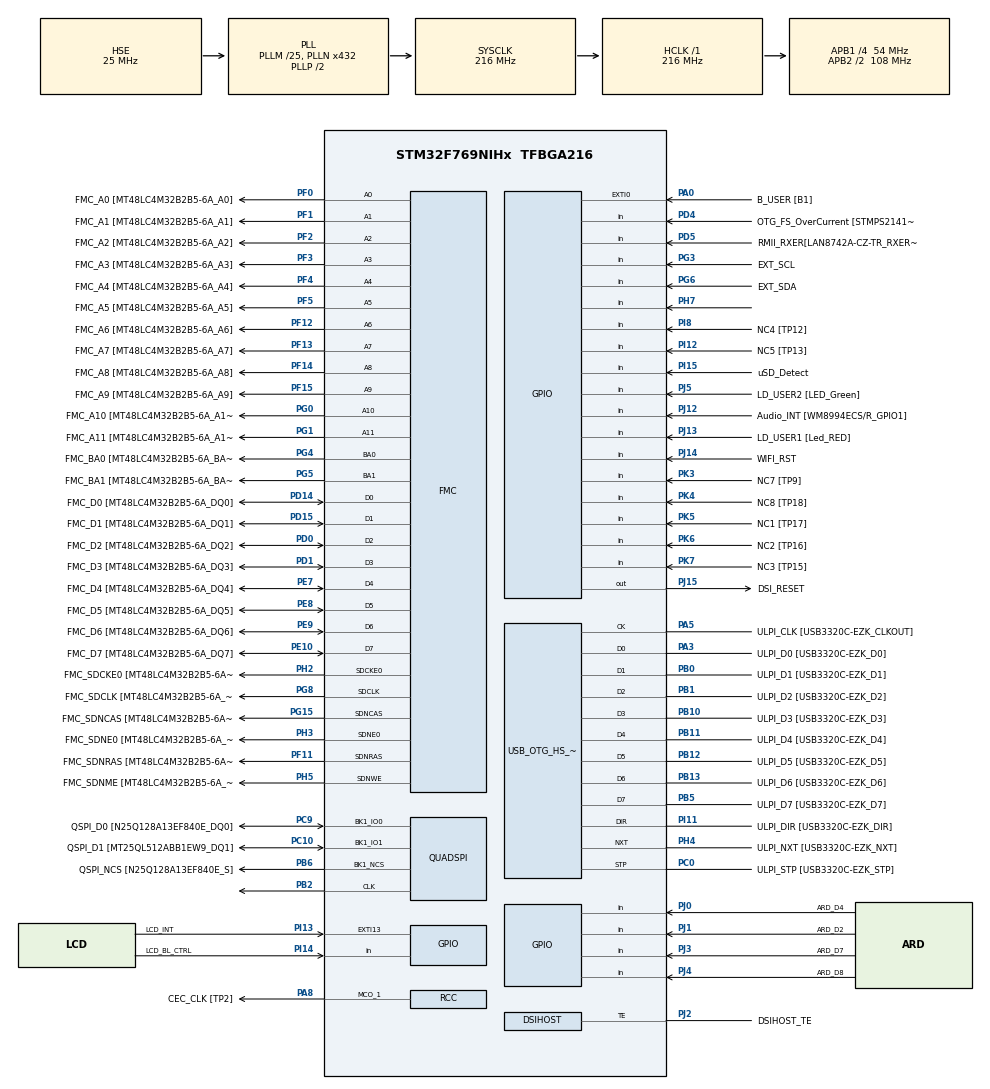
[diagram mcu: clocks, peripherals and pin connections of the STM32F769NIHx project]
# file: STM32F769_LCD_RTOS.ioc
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DSIHOST_CKN.GPIO_Label=DSI_CK_N
DSIHOST_CKN.Mode=DSIHost_Adapted_TE
DSIHOST_CKN.Signal=DSIHOST_CKN
DSIHOST_CKP.GPIO_Label=DSI_CK_P
DSIHOST_CKP.Mode=DSIHost_Adapted_TE
DSIHOST_CKP.Signal=DSIHOST_CKP
DSIHOST_D0N.GPIO_Label=DSI_D0_N
DSIHOST_D0N.Mode=DSIHost_Adapted_TE
DSIHOST_D0N.Signal=DSIHOST_D0N
DSIHOST_D0P.GPIO_Label=DSI_D0_p
DSIHOST_D0P.Mode=DSIHost_Adapted_TE
DSIHOST_D0P.Signal=DSIHOST_D0P
DSIHOST_D1N.GPIO_Label=DSI_D1_N
DSIHOST_D1N.Mode=DSIHost_Adapted_TE
DSIHOST_D1N.Signal=DSIHOST_D1N
DSIHOST_D1P.GPIO_Label=DSI_D1_P
DSIHOST_D1P.Mode=DSIHost_Adapted_TE
DSIHOST_D1P.Signal=DSIHOST_D1P
FREERTOS.Tasks01=defaultTask,24,4096,StartDefaultTask,Default,NULL,Dynamic,NULL,NULL
FREERTOS.configCHECK_FOR_STACK_OVERFLOW=2
FREERTOS.configTOTAL_HEAP_SIZE=32768
FREERTOS.configUSE_APPLICATION_TASK_TAG=1
FREERTOS.configUSE_COUNTING_SEMAPHORES=1
FREERTOS.configUSE_IDLE_HOOK=1
FREERTOS.configUSE_MALLOC_FAILED_HOOK=1
FREERTOS.configUSE_RECURSIVE_MUTEXES=1
LTDC.ActiveW=200
LTDC.Alpha_L0=255
LTDC.BlendingFactor1_L0=LTDC_BLENDING_FACTOR1_PAxCA
LTDC.BlendingFactor2_L0=LTDC_BLENDING_FACTOR2_PAxCA
LTDC.FBStartAdress_L0=0xC0000000
LTDC.HBP=1
LTDC.HFP=1
LTDC.HSync=1
LTDC.ImageHeight_L0=480
LTDC.ImageWidth_L0=200
LTDC.Layers=0
LTDC.PixelFormat_L0=LTDC_PIXEL_FORMAT_RGB565
LTDC.VBP=1
LTDC.VFP=1
LTDC.VSync=1
LTDC.WindowX1_L0=200
LTDC.WindowY1_L0=480
Mcu.Family=STM32F7
Mcu.Name=STM32F769NIHx
Mcu.Package=TFBGA216
NVIC.DMA2D_IRQn=true\:5\:0\:false\:false\:true\:true\:true\:true
NVIC.LTDC_IRQn=true\:5\:0\:false\:false\:true\:true\:true\:true
NVIC.OTG_HS_IRQn=true\:5\:0\:false\:false\:true\:true\:true\:true
NVIC.PriorityGroup=NVIC_PRIORITYGROUP_4
NVIC.TIM6_DAC_IRQn=true\:0\:0\:false\:false\:true\:false\:false\:true
NVIC.TimeBase=TIM6_DAC_IRQn
NVIC.TimeBaseIP=TIM6
PA0/WKUP.GPIO_Label=B_USER [B1]
PA0/WKUP.Signal=GPXTI0
PA1.GPIO_Label=RMII_REF_CLK [LAN8742A-CZ-TR_REFCLK0]
PA1.Signal=ETH_REF_CLK
PA10.GPIO_Label=VCP_RX 
PA10.Signal=USART1_RX
PA11.GPIO_Label=SPI2_NSS
PA11.Signal=SPI2_NSS
PA12.GPIO_Label=ARD_D13/SCK
PA12.GPIO_Mode=GPIO_MODE_AF_PP
PA12.GPIO_PuPd=GPIO_NOPULL
PA12.GPIO_Speed=GPIO_SPEED_FREQ_LOW
PA12.Signal=SPI2_SCK
PA13.GPIO_Label=SWDIO
PA13.Mode=Serial_Wire
PA13.Signal=SYS_JTMS-SWDIO
PA14.GPIO_Label=SWCLK
PA14.Mode=Serial_Wire
PA14.Signal=SYS_JTCK-SWCLK
PA15.GPIO_Label=CEC
PA15.Signal=CEC
PA2.GPIO_Label=RMII_MDIO [LAN8742A-CZ-TR_MDIO]
PA2.Signal=ETH_MDIO
PA3.GPIO_Label=ULPI_D0 [USB3320C-EZK_D0]
PA3.Mode=Device_HS
PA3.Signal=USB_OTG_HS_ULPI_D0
PA4.GPIO_Label=ARD_A1
PA4.Signal=ADCx_IN4
PA5.GPIO_Label=ULPI_CLK [USB3320C-EZK_CLKOUT]
PA5.Mode=Device_HS
PA5.Signal=USB_OTG_HS_ULPI_CK
PA6.GPIO_Label=ARD_A0
PA6.Signal=ADCx_IN6
PA7.GPIO_Label=RMII_CRS_DV [LAN8742A-CZ-TR_CRS_DV]
PA7.Signal=ETH_CRS_DV
PA8.GPIO_Label=CEC_CLK [TP2]
PA8.Mode=Clock-out-1
PA8.Signal=RCC_MCO_1
PA9.GPIO_Label=VCP_TX [STM32F103CBT6_PA3]
PA9.GPIO_Mode=GPIO_MODE_AF_PP
PA9.GPIO_PuPd=GPIO_NOPULL
PA9.GPIO_Speed=GPIO_SPEED_FREQ_LOW
PA9.Signal=USART1_TX
PB0.GPIO_Label=ULPI_D1 [USB3320C-EZK_D1]
PB0.Mode=Device_HS
PB0.Signal=USB_OTG_HS_ULPI_D1
PB1.GPIO_Label=ULPI_D2 [USB3320C-EZK_D2]
PB1.Mode=Device_HS
PB1.Signal=USB_OTG_HS_ULPI_D2
PB10.GPIO_Label=ULPI_D3 [USB3320C-EZK_D3]
PB10.Mode=Device_HS
PB10.Signal=USB_OTG_HS_ULPI_D3
PB11.GPIO_Label=ULPI_D4 [USB3320C-EZK_D4]
PB11.Mode=Device_HS
PB11.Signal=USB_OTG_HS_ULPI_D4
PB12.GPIO_Label=ULPI_D5 [USB3320C-EZK_D5]
PB12.Mode=Device_HS
PB12.Signal=USB_OTG_HS_ULPI_D5
PB13.GPIO_Label=ULPI_D6 [USB3320C-EZK_D6]
PB13.Mode=Device_HS
PB13.Signal=USB_OTG_HS_ULPI_D6
PB14.GPIO_Label=ARDUINO MISO/D12
PB14.GPIO_Mode=GPIO_MODE_AF_PP
PB14.GPIO_PuPd=GPIO_NOPULL
PB14.GPIO_Speed=GPIO_SPEED_FREQ_LOW
PB14.Signal=SPI2_MISO
PB15.GPIO_Label=ARDUINO MOSI/PWM/D11
PB15.GPIO_Mode=GPIO_MODE_AF_PP
PB15.GPIO_PuPd=GPIO_NOPULL
PB15.GPIO_Speed=GPIO_SPEED_FREQ_LOW
PB15.Signal=SPI2_MOSI
PB2.Mode=Single Bank 1 2IOs
PB2.Signal=QUADSPI_CLK
PB3.GPIO_Label=uSD_D2
PB3.Signal=SDMMC2_D2
PB4.GPIO_Label=uSD_D3
PB4.Signal=SDMMC2_D3
PB5.GPIO_Label=ULPI_D7 [USB3320C-EZK_D7]
PB5.Mode=Device_HS
PB5.Signal=USB_OTG_HS_ULPI_D7
PB6.GPIO_Label=QSPI_NCS [N25Q128A13EF840E_S]
PB6.Mode=Single Bank 1 2IOs
PB6.Signal=QUADSPI_BK1_NCS
PB7.GPIO_Label=AUDIO_SDA [WM8994ECS/R_SDA]
PB7.Signal=I2C4_SDA
PB8.GPIO_Label=ARDUINO SCL/D15
PB8.GPIO_Mode=GPIO_MODE_AF_OD
PB8.GPIO_PuPd=GPIO_NOPULL
PB8.GPIO_Speed=GPIO_SPEED_FREQ_LOW
PB8.Signal=I2C1_SCL
PB9.GPIO_Label=ARDUINO SDA/D14
PB9.GPIO_Mode=GPIO_MODE_AF_OD
PB9.GPIO_PuPd=GPIO_NOPULL
PB9.GPIO_Speed=GPIO_SPEED_FREQ_LOW
PB9.Signal=I2C1_SDA
PC0.GPIO_Label=ULPI_STP [USB3320C-EZK_STP]
PC0.Mode=Device_HS
PC0.Signal=USB_OTG_HS_ULPI_STP
PC1.GPIO_Label=RMII_MDC [LAN8742A-CZ-TR_MDC]
PC1.Signal=ETH_MDC
PC10.GPIO_Label=QSPI_D1 [MT25QL512ABB1EW9_DQ1]
PC10.Mode=Single Bank 1 2IOs
PC10.Signal=QUADSPI_BK1_IO1
PC11.GPIO_Label=DFSDM_DATIN5 [TP5]
PC11.Signal=S_DATAIN5DFSDM1
PC12.GPIO_Label=WIFI_RX
PC12.Signal=UART5_TX
PC13.Signal=RTC_OUT_ALARM
PC14/OSC32_IN.GPIO_Label=RCC_OSC32_IN
PC14/OSC32_IN.Mode=LSE-External-Oscillator
PC14/OSC32_IN.Signal=RCC_OSC32_IN
PC15/OSC32_OUT.GPIO_Label=RCC_OSC32_OUT
PC15/OSC32_OUT.Mode=LSE-External-Oscillator
PC15/OSC32_OUT.Signal=RCC_OSC32_OUT
PC2.GPIO_Label=ARD_A2
PC2.Signal=ADCx_IN12
PC4.GPIO_Label=RMII_RXD0 [LAN8742A-CZ-TR_RXD0]
PC4.Signal=ETH_RXD0
PC5.GPIO_Label=RMII_RXD1 [LAN8742A-CZ-TR_RXD1]
PC5.Signal=ETH_RXD1
PC6.GPIO_Label=ARDUINO TX/D1
PC6.Signal=USART6_TX
PC7.GPIO_Label=ARD_D0/RX
PC7.Signal=USART6_RX
PC8.GPIO_Label=ARD_D5/PWM
PC8.Signal=S_TIM3_CH3
PC9.GPIO_Label=QSPI_D0 [N25Q128A13EF840E_DQ0]
PC9.Mode=Single Bank 1 2IOs
PC9.Signal=QUADSPI_BK1_IO0
PD0.GPIO_Label=FMC_D2 [MT48LC4M32B2B5-6A_DQ2]
PD0.Signal=FMC_D2_DA2
PD1.GPIO_Label=FMC_D3 [MT48LC4M32B2B5-6A_DQ3]
PD1.Signal=FMC_D3_DA3
PD10.GPIO_Label=FMC_D15 [MT48LC4M32B2B5-6A_DQ15]
PD10.Signal=FMC_D15_DA15
PD11.GPIO_Label=SPDIF_TX [TP20]
PD11.Signal=SAI2_SD_A
PD12.GPIO_Label=AUDIO_SCL [WM8994ECS/R_SCLK]
PD12.Signal=I2C4_SCL
PD13.GPIO_Label=QSPI_D3 [N25Q128A13EF840E_DQ3]
PD13.Signal=QUADSPI_BK1_IO3
PD14.GPIO_Label=FMC_D0 [MT48LC4M32B2B5-6A_DQ0]
PD14.Signal=FMC_D0_DA0
PD15.GPIO_Label=FMC_D1 [MT48LC4M32B2B5-6A_DQ1]
PD15.Signal=FMC_D1_DA1
PD2.GPIO_Label=WIFI_TX
PD2.Signal=UART5_RX
PD3.GPIO_Label=DFSDM_CKOUT [TP102]
PD3.Signal=S_CKOUTDFSDM1
PD4.GPIO_Label=OTG_FS_OverCurrent [STMPS2141STR_Fault]
PD4.Signal=GPIO_Input
PD5.GPIO_Label=RMII_RXER[LAN8742A-CZ-TR_RXERR]
PD5.Signal=GPIO_Input
PD6.GPIO_Label=uSD_CLK
PD6.Signal=SDMMC2_CK
PD7.GPIO_Label=uSD_CMD
PD7.Signal=SDMMC2_CMD
PD8.GPIO_Label=FMC_D13 [MT48LC4M32B2B5-6A_DQ13]
PD8.Signal=FMC_D13_DA13
PD9.GPIO_Label=FMC_D14 [MT48LC4M32B2B5-6A_DQ14]
PD9.Signal=FMC_D14_DA14
PE0.GPIO_Label=FMC_NBL0 [MT48LC4M32B2B5-6A_DQM0]
PE0.Signal=FMC_NBL0
PE1.GPIO_Label=FMC_NBL1 [MT48LC4M32B2B5-6A_DQM1]
PE1.Signal=FMC_NBL1
PE10.GPIO_Label=FMC_D7 [MT48LC4M32B2B5-6A_DQ7]
PE10.Signal=FMC_D7_DA7
PE11.GPIO_Label=FMC_D8 [MT48LC4M32B2B5-6A_DQ8]
PE11.Signal=FMC_D8_DA8
PE12.GPIO_Label=FMC_D9 [MT48LC4M32B2B5-6A_DQ9]
PE12.Signal=FMC_D9_DA9
PE13.GPIO_Label=FMC_D10 [MT48LC4M32B2B5-6A_DQ10]
PE13.Signal=FMC_D10_DA10
PE14.GPIO_Label=FMC_D11 [MT48LC4M32B2B5-6A_DQ11]
PE14.Signal=FMC_D11_DA11
PE15.GPIO_Label=FMC_D12 [MT48LC4M32B2B5-6A_DQ12]
PE15.Signal=FMC_D12_DA12
PE2.GPIO_Label=QSPI_D2 [N25Q128A13EF840E_DQ2]
PE2.Signal=QUADSPI_BK1_IO2
PE3.GPIO_Label=SAI1_SDB [WM8994ECS/R_ADCDAT1]
PE3.Signal=SAI1_SD_B
PE4.GPIO_Label=SAI1_FSA [WM8994ECS/R_LRCLK1]
PE4.Signal=SAI1_FS_A
PE5.GPIO_Label=SAI1_SCKA [WM8994ECS/R_BCLK1]
PE5.Signal=SAI1_SCK_A
PE6.GPIO_Label=SAI1_SDA [WM8994ECS/R_DACDAT1]
PE6.Signal=SAI1_SD_A
PE7.GPIO_Label=FMC_D4 [MT48LC4M32B2B5-6A_DQ4]
PE7.Signal=FMC_D4_DA4
PE8.GPIO_Label=FMC_D5 [MT48LC4M32B2B5-6A_DQ5]
PE8.Signal=FMC_D5_DA5
PE9.GPIO_Label=FMC_D6 [MT48LC4M32B2B5-6A_DQ6]
PE9.Signal=FMC_D6_DA6
PF0.GPIO_Label=FMC_A0 [MT48LC4M32B2B5-6A_A0]
PF0.Signal=FMC_A0
PF1.GPIO_Label=FMC_A1 [MT48LC4M32B2B5-6A_A1]
PF1.Signal=FMC_A1
PF10.GPIO_Label=ARDUINO A1
PF10.GPIO_Mode=GPIO_MODE_ANALOG
PF10.GPIO_PuPd=GPIO_NOPULL
PF10.Signal=ADC3_IN8
PF11.GPIO_Label=FMC_SDNRAS [MT48LC4M32B2B5-6A_RAS]
PF11.Signal=FMC_SDNRAS
PF12.GPIO_Label=FMC_A6 [MT48LC4M32B2B5-6A_A6]
PF12.Signal=FMC_A6
PF13.GPIO_Label=FMC_A7 [MT48LC4M32B2B5-6A_A7]
PF13.Signal=FMC_A7
PF14.GPIO_Label=FMC_A8 [MT48LC4M32B2B5-6A_A8]
PF14.Signal=FMC_A8
PF15.GPIO_Label=FMC_A9 [MT48LC4M32B2B5-6A_A9]
PF15.Signal=FMC_A9
PF2.GPIO_Label=FMC_A2 [MT48LC4M32B2B5-6A_A2]
PF2.Signal=FMC_A2
PF3.GPIO_Label=FMC_A3 [MT48LC4M32B2B5-6A_A3]
PF3.Signal=FMC_A3
PF4.GPIO_Label=FMC_A4 [MT48LC4M32B2B5-6A_A4]
PF4.Signal=FMC_A4
PF5.GPIO_Label=FMC_A5 [MT48LC4M32B2B5-6A_A5]
PF5.Signal=FMC_A5
PF6.GPIO_Label=ARD_D3/PWM
PF6.Signal=S_TIM10_CH1
PF7.GPIO_Label=ARD_D6/PWM
PF7.Signal=S_TIM11_CH1
PF8.GPIO_Label=ARDUINO A3
PF8.GPIO_Mode=GPIO_MODE_ANALOG
PF8.GPIO_PuPd=GPIO_NOPULL
PF8.Signal=ADC3_IN6
PF9.GPIO_Label=ARDUINO A2
PF9.GPIO_Mode=GPIO_MODE_ANALOG
PF9.GPIO_PuPd=GPIO_NOPULL
PF9.Signal=ADC3_IN7
PG0.GPIO_Label=FMC_A10 [MT48LC4M32B2B5-6A_A10]
PG0.Signal=FMC_A10
PG1.GPIO_Label=FMC_A11 [MT48LC4M32B2B5-6A_A11]
PG1.Signal=FMC_A11
PG10.GPIO_Label=uSD_D1
PG10.Signal=SDMMC2_D1
PG11.GPIO_Label=RMII_TX_EN [LAN8742A-CZ-TR_TXEN]
PG11.Signal=ETH_TX_EN
PG12.GPIO_Label=SPDIF_RX [74LVC1G04SE_4]
PG12.Signal=SPDIFRX_IN1
PG13.GPIO_Label=RMII_TXD0 [LAN8742A-CZ-TR_TXD0]
PG13.Signal=ETH_TXD0
PG14.GPIO_Label=RMII_TXD1 [LAN8742A-CZ-TR_TXD1]
PG14.Signal=ETH_TXD1
PG15.GPIO_Label=FMC_SDNCAS [MT48LC4M32B2B5-6A_CAS]
PG15.Signal=FMC_SDNCAS
PG2.GPIO_Label=FMC_A12
PG2.Signal=FMC_A12
PG3.GPIO_Label=EXT_SCL
PG3.Signal=GPIO_Input
PG4.GPIO_Label=FMC_BA0 [MT48LC4M32B2B5-6A_BA0]
PG4.Signal=FMC_A14_BA0
PG5.GPIO_Label=FMC_BA1 [MT48LC4M32B2B5-6A_BA1]
PG5.Signal=FMC_A15_BA1
PG6.GPIO_Label=EXT_SDA
PG6.Signal=GPIO_Input
PG7.GPIO_Label=SAI1_MCLKA [WM8994ECS/R_MCLK1]
PG7.Signal=SAI1_MCLK_A
PG8.GPIO_Label=FMC_SDCLK [MT48LC4M32B2B5-6A_CLK]
PG8.Signal=FMC_SDCLK
PG9.GPIO_Label=uSD_D0
PG9.Signal=SDMMC2_D0
PH0/OSC_IN.GPIO_Label=OSC_25M [NZ2520SB-25.00M_OUT]
PH0/OSC_IN.Mode=HSE-External-Oscillator
PH0/OSC_IN.Signal=RCC_OSC_IN
PH1/OSC_OUT.Mode=HSE-External-Oscillator
PH1/OSC_OUT.Signal=RCC_OSC_OUT
PH10.GPIO_Label=FMC_D18 [MT48LC4M32B2B5-6A_DQ18]
PH10.Signal=FMC_D18
PH11.GPIO_Label=FMC_D19 [MT48LC4M32B2B5-6A_DQ19]
PH11.Signal=FMC_D19
PH12.GPIO_Label=D20
PH12.Signal=FMC_D20
PH13.GPIO_Label=D21
PH13.Signal=FMC_D21
PH14.GPIO_Label=D22
PH14.Signal=FMC_D22
PH15.GPIO_Label=D23
PH15.Signal=FMC_D23
PH2.GPIO_Label=FMC_SDCKE0 [MT48LC4M32B2B5-6A_CKE]
PH2.Mode=SdramChipSelect1_2
PH2.Signal=FMC_SDCKE0
PH3.GPIO_Label=FMC_SDNE0 [MT48LC4M32B2B5-6A_CS]
PH3.Mode=SdramChipSelect1_2
PH3.Signal=FMC_SDNE0
PH4.GPIO_Label=ULPI_NXT [USB3320C-EZK_NXT]
PH4.Mode=Device_HS
PH4.Signal=USB_OTG_HS_ULPI_NXT
PH5.GPIO_Label=FMC_SDNME [MT48LC4M32B2B5-6A_WE]
PH5.Signal=FMC_SDNWE
PH6.GPIO_Label=ARDUINO PWM/D6
PH6.Signal=S_TIM12_CH1
PH7.Signal=GPIO_Input
PH8.GPIO_Label=FMC_D16 [MT48LC4M32B2B5-6A_DQ16]
PH8.Signal=FMC_D16
PH9.GPIO_Label=FMC_D\!7 [MT48LC4M32B2B5-6A_DQ17]
PH9.Signal=FMC_D17
PI0.GPIO_Label=D24
PI0.Signal=FMC_D24
PI1.GPIO_Label=D25
PI1.Signal=FMC_D25
PI10.GPIO_Label=D31
PI10.Signal=FMC_D31
PI11.GPIO_Label=ULPI_DIR [USB3320C-EZK_DIR]
PI11.Mode=Device_HS
PI11.Signal=USB_OTG_HS_ULPI_DIR
PI12.GPIO_Label=NC5 [TP13]
PI12.Signal=GPIO_Input
PI13.GPIO_Label=LCD_INT
PI13.GPIO_ModeDefaultEXTI=GPIO_MODE_EVT_RISING
PI13.Signal=GPXTI13
PI14.GPIO_Label=LCD_BL_CTRL
PI14.Signal=GPIO_Input
PI15.GPIO_Label=uSD_Detect
PI15.Signal=GPIO_Input
PI2.GPIO_Label=D26
PI2.Signal=FMC_D26
PI3.GPIO_Label=D27
PI3.Signal=FMC_D27
PI4.GPIO_Label=FMC_NBL2 [MT48LC4M32B2B5-6A_DQM2]
PI4.Signal=FMC_NBL2
PI5.GPIO_Label=FMC_NBL3 [MT48LC4M32B2B5-6A_DQM3]
PI5.Signal=FMC_NBL3
PI6.GPIO_Label=D28
PI6.Signal=FMC_D28
PI7.GPIO_Label=D29
PI7.Signal=FMC_D29
PI8.GPIO_Label=NC4 [TP12]
PI8.Signal=GPIO_Input
PI9.GPIO_Label=D30
PI9.Signal=FMC_D30
PJ0.GPIO_Label=ARD_D4
PJ0.Signal=GPIO_Input
PJ1.GPIO_Label=ARD_D2
PJ1.Signal=GPIO_Input
PJ12.GPIO_Label=Audio_INT [WM8994ECS/R_GPIO1]
PJ12.Signal=GPIO_Input
PJ13.GPIO_Label=LD_USER1 [Led_RED]
PJ13.Signal=GPIO_Input
PJ14.GPIO_Label=WIFI_RST
PJ14.Signal=GPIO_Input
PJ15.GPIO_Label=DSI_RESET
PJ15.Signal=GPIO_Output
PJ2.GPIO_Label=DSIHOST_TE
PJ2.Mode=DSIHost_Adapted_TE
PJ2.Signal=DSIHOST_TE
PJ3.GPIO_Label=ARD_D7
PJ3.Signal=GPIO_Input
PJ4.GPIO_Label=ARD_D8
PJ4.Signal=GPIO_Input
PJ5.GPIO_Label=LD_USER2 [LED_Green]
PJ5.Signal=GPIO_Input
PK3.GPIO_Label=NC7 [TP9]
PK3.Signal=GPIO_Input
PK4.GPIO_Label=NC8 [TP18]
PK4.Signal=GPIO_Input
PK5.GPIO_Label=NC1 [TP17]
PK5.Signal=GPIO_Input
PK6.GPIO_Label=NC2 [TP16]
PK6.Signal=GPIO_Input
PK7.GPIO_Label=NC3 [TP15]
PK7.Signal=GPIO_Input
ProjectManager.HeapSize=0x200
ProjectManager.StackSize=0x400
ProjectManager.TargetToolchain=STM32CubeIDE
RCC.AHBFreq_Value=216000000
RCC.APB1CLKDivider=RCC_HCLK_DIV4
RCC.APB1Freq_Value=54000000
RCC.APB1TimFreq_Value=108000000
RCC.APB2CLKDivider=RCC_HCLK_DIV2
RCC.APB2Freq_Value=108000000
RCC.APB2TimFreq_Value=216000000
RCC.CortexFreq_Value=216000000
RCC.HCLKFreq_Value=216000000
RCC.HSE_VALUE=25000000
RCC.HSI_VALUE=16000000
RCC.PLL48CLockSelection=RCC_CLK48SOURCE_PLLSAIP
RCC.PLLM=25
RCC.PLLN=432
RCC.PLLQ=4
RCC.PLLSAIP=RCC_PLLSAIP_DIV4
RCC.PLLSAIQ=3
RCC.PLLSourceVirtual=RCC_PLLSOURCE_HSE
RCC.SDMMC2ClockSelection=RCC_SDMMC2CLKSOURCE_CLK48
RCC.SYSCLKFreq_VALUE=216000000
RCC.SYSCLKSource=RCC_SYSCLKSOURCE_PLLCLK
RCC.USBFreq_Value=48000000
RCC.VCOOutputFreq_Value=432000000
SH.ADCx_IN12.0=ADC1_IN12
SH.ADCx_IN4.0=ADC1_IN4
SH.ADCx_IN6.0=ADC1_IN6
SH.FMC_A0.0=FMC_A0,12b-sda2
SH.FMC_A1.0=FMC_A1,12b-sda2
SH.FMC_A10.0=FMC_A10,12b-sda2
SH.FMC_A11.0=FMC_A11,12b-sda2
SH.FMC_A12.0=FMC_A12
SH.FMC_A14_BA0.0=FMC_BA0,FourSdramBanks2
SH.FMC_A15_BA1.0=FMC_BA1,FourSdramBanks2
SH.FMC_A2.0=FMC_A2,12b-sda2
SH.FMC_A3.0=FMC_A3,12b-sda2
SH.FMC_A4.0=FMC_A4,12b-sda2
SH.FMC_A5.0=FMC_A5,12b-sda2
SH.FMC_A6.0=FMC_A6,12b-sda2
SH.FMC_A7.0=FMC_A7,12b-sda2
SH.FMC_A8.0=FMC_A8,12b-sda2
SH.FMC_A9.0=FMC_A9,12b-sda2
SH.FMC_D0_DA0.0=FMC_D0,sd-8b-d2
SH.FMC_D10_DA10.0=FMC_D10
SH.FMC_D11_DA11.0=FMC_D11
SH.FMC_D12_DA12.0=FMC_D12
SH.FMC_D13_DA13.0=FMC_D13
SH.FMC_D14_DA14.0=FMC_D14
SH.FMC_D15_DA15.0=FMC_D15
SH.FMC_D16.0=FMC_D16
SH.FMC_D17.0=FMC_D17
SH.FMC_D18.0=FMC_D18
SH.FMC_D19.0=FMC_D19
SH.FMC_D1_DA1.0=FMC_D1,sd-8b-d2
SH.FMC_D20.0=FMC_D20
SH.FMC_D21.0=FMC_D21
SH.FMC_D22.0=FMC_D22
SH.FMC_D23.0=FMC_D23
SH.FMC_D24.0=FMC_D24
SH.FMC_D25.0=FMC_D25
SH.FMC_D26.0=FMC_D26
SH.FMC_D27.0=FMC_D27
SH.FMC_D28.0=FMC_D28
SH.FMC_D29.0=FMC_D29
SH.FMC_D2_DA2.0=FMC_D2,sd-8b-d2
SH.FMC_D30.0=FMC_D30
SH.FMC_D31.0=FMC_D31
SH.FMC_D3_DA3.0=FMC_D3,sd-8b-d2
SH.FMC_D4_DA4.0=FMC_D4,sd-8b-d2
SH.FMC_D5_DA5.0=FMC_D5,sd-8b-d2
SH.FMC_D6_DA6.0=FMC_D6,sd-8b-d2
SH.FMC_D7_DA7.0=FMC_D7,sd-8b-d2
SH.FMC_D8_DA8.0=FMC_D8
SH.FMC_D9_DA9.0=FMC_D9
SH.FMC_NBL0.0=FMC_NBL0
SH.FMC_NBL1.0=FMC_NBL1
SH.FMC_NBL2.0=FMC_NBL2
SH.FMC_NBL3.0=FMC_NBL3
SH.FMC_SDCLK.0=FMC_SDCLK,12b-sda2
SH.FMC_SDNCAS.0=FMC_SDNCAS,12b-sda2
SH.FMC_SDNRAS.0=FMC_SDNRAS,12b-sda2
SH.FMC_SDNWE.0=FMC_SDNWE,12b-sda2
SH.S_CKOUTDFSDM1.0=DFSDM1_CKOUT
SH.S_DATAIN5DFSDM1.0=DFSDM1_DATIN5
SH.S_TIM10_CH1.0=TIM10_CH1
SH.S_TIM11_CH1.0=TIM11_CH1
SH.S_TIM12_CH1.0=TIM12_CH1
SH.S_TIM3_CH3.0=TIM3_CH3
USB_OTG_HS.VirtualMode-Device_HS=Device_HS
VP_DMA2D_VS_DMA2D.Mode=DMA2D_Activate
VP_FREERTOS_VS_CMSIS_V2.Mode=CMSIS_V2
VP_LTDC_DSIMode.Mode=RGB888
VP_SYS_VS_tim6.Mode=TIM6
VP_WWDG_VS_WWDG.Mode=WWDG_Activate
WWDG.Counter=128
board=STM32F769I-DISCO

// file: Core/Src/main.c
/* USER CODE BEGIN Header */
/**
  ******************************************************************************
  * @file           : main.c
  * @brief          : Main program body
  ******************************************************************************
  * @attention
  *
  * <h2><center>&copy; Copyright (c) 2019 STMicroelectronics.
  * All rights reserved.</center></h2>
  *
  * This software component is licensed by ST under Ultimate Liberty license
  * SLA0044, the "License"; You may not use this file except in compliance with
  * the License. You may obtain a copy of the License at:
  *                             www.st.com/SLA0044
  *
  ******************************************************************************
  */
/* USER CODE END Header */

#include "main.h"
#include "cmsis_os.h"

/* USER CODE BEGIN Includes */
#include "../../Drivers/BSP/STM32F769I-Discovery/stm32f769i_discovery.h"
#include "../../Drivers/BSP/STM32F769I-Discovery/stm32f769i_discovery_ts.h"
#include "../../Drivers/BSP/STM32F769I-Discovery/stm32f769i_discovery_lcd.h"
/* USER CODE END Includes */

DMA2D_HandleTypeDef hdma2d;

DSI_HandleTypeDef hdsi;

LTDC_HandleTypeDef hltdc;

QSPI_HandleTypeDef hqspi;

PCD_HandleTypeDef hpcd_USB_OTG_HS;

WWDG_HandleTypeDef hwwdg;

SDRAM_HandleTypeDef hsdram2;

osThreadId_t defaultTaskHandle;
/* USER CODE BEGIN PV */
osThreadId_t LCDTaskHandle;
/* USER CODE END PV */

void SystemClock_Config(void);
static void MX_GPIO_Init(void);
static void MX_DMA2D_Init(void);
static void MX_DSIHOST_DSI_Init(void);
static void MX_FMC_Init(void);
static void MX_LTDC_Init(void);
static void MX_QUADSPI_Init(void);
static void MX_USB_OTG_HS_PCD_Init(void);
static void MX_WWDG_Init(void);
void StartDefaultTask(void *argument);

/* USER CODE BEGIN PFP */
void LCDTask(void *argument);
/* USER CODE END PFP */

int main(void)
{

  /* MCU Configuration--------------------------------------------------------*/

  /* Reset of all peripherals, Initializes the Flash interface and the Systick. */
  HAL_Init();

  /* Configure the system clock */
  SystemClock_Config();

  /* Initialize all configured peripherals */

  /* USER CODE BEGIN 2 */
  BSP_LCD_Init();

  /* USER CODE END 2 */

  osKernelInitialize();

  /* Create the thread(s) */
  /* definition and creation of defaultTask */
  const osThreadAttr_t defaultTask_attributes = {
    .name = "defaultTask",
    .priority = (osPriority_t) osPriorityNormal,
    .stack_size = 4096
  };
  defaultTaskHandle = osThreadNew(StartDefaultTask, NULL, &defaultTask_attributes);

  /* USER CODE BEGIN RTOS_THREADS */
  /* add threads, ... */
  const osThreadAttr_t LCDtask_attributes = {
    .name = "LCDTask",
    .priority = (osPriority_t) osPriorityNormal,
    .stack_size = 4096
  };

  LCDTaskHandle = osThreadNew(LCDTask, NULL, &LCDtask_attributes);
  /* USER CODE END RTOS_THREADS */

  /* Start scheduler */
  osKernelStart();

  /* We should never get here as control is now taken by the scheduler */

  /* Infinite loop */
  while (1)
  {

  }
}

void SystemClock_Config(void)
{
  RCC_OscInitTypeDef RCC_OscInitStruct = {0};
  RCC_ClkInitTypeDef RCC_ClkInitStruct = {0};
  RCC_PeriphCLKInitTypeDef PeriphClkInitStruct = {0};

  /** Configure LSE Drive Capability
  */
  HAL_PWR_EnableBkUpAccess();
  /** Configure the main internal regulator output voltage
  */
  __HAL_RCC_PWR_CLK_ENABLE();
  __HAL_PWR_VOLTAGESCALING_CONFIG(PWR_REGULATOR_VOLTAGE_SCALE1);
  /** Initializes the CPU, AHB and APB busses clocks
  */
  RCC_OscInitStruct.OscillatorType = RCC_OSCILLATORTYPE_HSI|RCC_OSCILLATORTYPE_HSE;
  RCC_OscInitStruct.HSEState = RCC_HSE_ON;
  RCC_OscInitStruct.HSIState = RCC_HSI_ON;
  RCC_OscInitStruct.HSICalibrationValue = RCC_HSICALIBRATION_DEFAULT;
  RCC_OscInitStruct.PLL.PLLState = RCC_PLL_ON;
  RCC_OscInitStruct.PLL.PLLSource = RCC_PLLSOURCE_HSE;
  RCC_OscInitStruct.PLL.PLLM = 25;
  RCC_OscInitStruct.PLL.PLLN = 432;
  RCC_OscInitStruct.PLL.PLLP = RCC_PLLP_DIV2;
  RCC_OscInitStruct.PLL.PLLQ = 4;
  if (HAL_RCC_OscConfig(&RCC_OscInitStruct) != HAL_OK)
  {
    Error_Handler();
  }
  /** Activate the Over-Drive mode
  */
  if (HAL_PWREx_EnableOverDrive() != HAL_OK)
  {
    Error_Handler();
  }
  /** Initializes the CPU, AHB and APB busses clocks
  */
  RCC_ClkInitStruct.ClockType = RCC_CLOCKTYPE_HCLK|RCC_CLOCKTYPE_SYSCLK
                              |RCC_CLOCKTYPE_PCLK1|RCC_CLOCKTYPE_PCLK2;
  RCC_ClkInitStruct.SYSCLKSource = RCC_SYSCLKSOURCE_PLLCLK;
  RCC_ClkInitStruct.AHBCLKDivider = RCC_SYSCLK_DIV1;
  RCC_ClkInitStruct.APB1CLKDivider = RCC_HCLK_DIV4;
  RCC_ClkInitStruct.APB2CLKDivider = RCC_HCLK_DIV2;

  if (HAL_RCC_ClockConfig(&RCC_ClkInitStruct, FLASH_LATENCY_7) != HAL_OK)
  {
    Error_Handler();
  }
  PeriphClkInitStruct.PeriphClockSelection = RCC_PERIPHCLK_LTDC;
  PeriphClkInitStruct.PLLSAI.PLLSAIN = 192;
  PeriphClkInitStruct.PLLSAI.PLLSAIR = 2;
  PeriphClkInitStruct.PLLSAI.PLLSAIQ = 3;
  PeriphClkInitStruct.PLLSAI.PLLSAIP = RCC_PLLSAIP_DIV4;
  PeriphClkInitStruct.PLLSAIDivQ = 1;
  PeriphClkInitStruct.PLLSAIDivR = RCC_PLLSAIDIVR_2;
  if (HAL_RCCEx_PeriphCLKConfig(&PeriphClkInitStruct) != HAL_OK)
  {
    Error_Handler();
  }
  HAL_RCC_MCOConfig(RCC_MCO1, RCC_MCO1SOURCE_HSI, RCC_MCODIV_1);
}

static void MX_DMA2D_Init(void)
{

  hdma2d.Instance = DMA2D;
  hdma2d.Init.Mode = DMA2D_M2M;
  hdma2d.Init.ColorMode = DMA2D_OUTPUT_ARGB8888;
  hdma2d.Init.OutputOffset = 0;
  hdma2d.LayerCfg[1].InputOffset = 0;
  hdma2d.LayerCfg[1].InputColorMode = DMA2D_INPUT_ARGB8888;
  hdma2d.LayerCfg[1].AlphaMode = DMA2D_NO_MODIF_ALPHA;
  hdma2d.LayerCfg[1].InputAlpha = 0;
  hdma2d.LayerCfg[1].AlphaInverted = DMA2D_REGULAR_ALPHA;
  hdma2d.LayerCfg[1].RedBlueSwap = DMA2D_RB_REGULAR;
  if (HAL_DMA2D_Init(&hdma2d) != HAL_OK)
  {
    Error_Handler();
  }
  if (HAL_DMA2D_ConfigLayer(&hdma2d, 1) != HAL_OK)
  {
    Error_Handler();
  }

}

static void MX_DSIHOST_DSI_Init(void)
{

  DSI_PLLInitTypeDef PLLInit = {0};
  DSI_HOST_TimeoutTypeDef HostTimeouts = {0};
  DSI_PHY_TimerTypeDef PhyTimings = {0};
  DSI_LPCmdTypeDef LPCmd = {0};
  DSI_CmdCfgTypeDef CmdCfg = {0};

  hdsi.Instance = DSI;
  hdsi.Init.AutomaticClockLaneControl = DSI_AUTO_CLK_LANE_CTRL_DISABLE;
  hdsi.Init.TXEscapeCkdiv = 4;
  hdsi.Init.NumberOfLanes = DSI_ONE_DATA_LANE;
  PLLInit.PLLNDIV = 20;
  PLLInit.PLLIDF = DSI_PLL_IN_DIV1;
  PLLInit.PLLODF = DSI_PLL_OUT_DIV1;
  if (HAL_DSI_Init(&hdsi, &PLLInit) != HAL_OK)
  {
    Error_Handler();
  }
  HostTimeouts.TimeoutCkdiv = 1;
  HostTimeouts.HighSpeedTransmissionTimeout = 0;
  HostTimeouts.LowPowerReceptionTimeout = 0;
  HostTimeouts.HighSpeedReadTimeout = 0;
  HostTimeouts.LowPowerReadTimeout = 0;
  HostTimeouts.HighSpeedWriteTimeout = 0;
  HostTimeouts.HighSpeedWritePrespMode = DSI_HS_PM_DISABLE;
  HostTimeouts.LowPowerWriteTimeout = 0;
  HostTimeouts.BTATimeout = 0;
  if (HAL_DSI_ConfigHostTimeouts(&hdsi, &HostTimeouts) != HAL_OK)
  {
    Error_Handler();
  }
  PhyTimings.ClockLaneHS2LPTime = 28;
  PhyTimings.ClockLaneLP2HSTime = 33;
  PhyTimings.DataLaneHS2LPTime = 15;
  PhyTimings.DataLaneLP2HSTime = 25;
  PhyTimings.DataLaneMaxReadTime = 0;
  PhyTimings.StopWaitTime = 0;
  if (HAL_DSI_ConfigPhyTimer(&hdsi, &PhyTimings) != HAL_OK)
  {
    Error_Handler();
  }
  if (HAL_DSI_ConfigFlowControl(&hdsi, DSI_FLOW_CONTROL_BTA) != HAL_OK)
  {
    Error_Handler();
  }
  if (HAL_DSI_SetLowPowerRXFilter(&hdsi, 10000) != HAL_OK)
  {
    Error_Handler();
  }
  if (HAL_DSI_ConfigErrorMonitor(&hdsi, HAL_DSI_ERROR_NONE) != HAL_OK)
  {
    Error_Handler();
  }
  LPCmd.LPGenShortWriteNoP = DSI_LP_GSW0P_DISABLE;
  LPCmd.LPGenShortWriteOneP = DSI_LP_GSW1P_DISABLE;
  LPCmd.LPGenShortWriteTwoP = DSI_LP_GSW2P_DISABLE;
  LPCmd.LPGenShortReadNoP = DSI_LP_GSR0P_DISABLE;
  LPCmd.LPGenShortReadOneP = DSI_LP_GSR1P_DISABLE;
  LPCmd.LPGenShortReadTwoP = DSI_LP_GSR2P_DISABLE;
  LPCmd.LPGenLongWrite = DSI_LP_GLW_DISABLE;
  LPCmd.LPDcsShortWriteNoP = DSI_LP_DSW0P_DISABLE;
  LPCmd.LPDcsShortWriteOneP = DSI_LP_DSW1P_DISABLE;
  LPCmd.LPDcsShortReadNoP = DSI_LP_DSR0P_DISABLE;
  LPCmd.LPDcsLongWrite = DSI_LP_DLW_DISABLE;
  LPCmd.LPMaxReadPacket = DSI_LP_MRDP_DISABLE;
  LPCmd.AcknowledgeRequest = DSI_ACKNOWLEDGE_DISABLE;
  if (HAL_DSI_ConfigCommand(&hdsi, &LPCmd) != HAL_OK)
  {
    Error_Handler();
  }
  CmdCfg.VirtualChannelID = 0;
  CmdCfg.ColorCoding = DSI_RGB888;
  CmdCfg.CommandSize = 200;
  CmdCfg.TearingEffectSource = DSI_TE_EXTERNAL;
  CmdCfg.TearingEffectPolarity = DSI_TE_RISING_EDGE;
  CmdCfg.HSPolarity = DSI_HSYNC_ACTIVE_LOW;
  CmdCfg.VSPolarity = DSI_VSYNC_ACTIVE_LOW;
  CmdCfg.DEPolarity = DSI_DATA_ENABLE_ACTIVE_HIGH;
  CmdCfg.VSyncPol = DSI_VSYNC_FALLING;
  CmdCfg.AutomaticRefresh = DSI_AR_ENABLE;
  CmdCfg.TEAcknowledgeRequest = DSI_TE_ACKNOWLEDGE_DISABLE;
  if (HAL_DSI_ConfigAdaptedCommandMode(&hdsi, &CmdCfg) != HAL_OK)
  {
    Error_Handler();
  }
  if (HAL_DSI_SetGenericVCID(&hdsi, 0) != HAL_OK)
  {
    Error_Handler();
  }

}

static void MX_LTDC_Init(void)
{

  LTDC_LayerCfgTypeDef pLayerCfg = {0};

  hltdc.Instance = LTDC;
  hltdc.Init.HSPolarity = LTDC_HSPOLARITY_AL;
  hltdc.Init.VSPolarity = LTDC_VSPOLARITY_AL;
  hltdc.Init.DEPolarity = LTDC_DEPOLARITY_AL;
  hltdc.Init.PCPolarity = LTDC_PCPOLARITY_IPC;
  hltdc.Init.HorizontalSync = 0;
  hltdc.Init.VerticalSync = 0;
  hltdc.Init.AccumulatedHBP = 1;
  hltdc.Init.AccumulatedVBP = 1;
  hltdc.Init.AccumulatedActiveW = 201;
  hltdc.Init.AccumulatedActiveH = 481;
  hltdc.Init.TotalWidth = 202;
  hltdc.Init.TotalHeigh = 482;
  hltdc.Init.Backcolor.Blue = 0;
  hltdc.Init.Backcolor.Green = 0;
  hltdc.Init.Backcolor.Red = 0;
  if (HAL_LTDC_Init(&hltdc) != HAL_OK)
  {
    Error_Handler();
  }
  pLayerCfg.WindowX0 = 0;
  pLayerCfg.WindowX1 = 200;
  pLayerCfg.WindowY0 = 0;
  pLayerCfg.WindowY1 = 480;
  pLayerCfg.PixelFormat = LTDC_PIXEL_FORMAT_RGB565;
  pLayerCfg.Alpha = 255;
  pLayerCfg.Alpha0 = 0;
  pLayerCfg.BlendingFactor1 = LTDC_BLENDING_FACTOR1_PAxCA;
  pLayerCfg.BlendingFactor2 = LTDC_BLENDING_FACTOR2_PAxCA;
  pLayerCfg.FBStartAdress = 0xC0000000;
  pLayerCfg.ImageWidth = 200;
  pLayerCfg.ImageHeight = 480;
  pLayerCfg.Backcolor.Blue = 0;
  pLayerCfg.Backcolor.Green = 0;
  pLayerCfg.Backcolor.Red = 0;
  if (HAL_LTDC_ConfigLayer(&hltdc, &pLayerCfg, 0) != HAL_OK)
  {
    Error_Handler();
  }

}

static void MX_QUADSPI_Init(void)
{

  /* QUADSPI parameter configuration*/
  hqspi.Instance = QUADSPI;
  hqspi.Init.ClockPrescaler = 255;
  hqspi.Init.FifoThreshold = 1;
  hqspi.Init.SampleShifting = QSPI_SAMPLE_SHIFTING_NONE;
  hqspi.Init.FlashSize = 1;
  hqspi.Init.ChipSelectHighTime = QSPI_CS_HIGH_TIME_1_CYCLE;
  hqspi.Init.ClockMode = QSPI_CLOCK_MODE_0;
  hqspi.Init.FlashID = QSPI_FLASH_ID_1;
  hqspi.Init.DualFlash = QSPI_DUALFLASH_DISABLE;
  if (HAL_QSPI_Init(&hqspi) != HAL_OK)
  {
    Error_Handler();
  }

}

static void MX_USB_OTG_HS_PCD_Init(void)
{

  hpcd_USB_OTG_HS.Instance = USB_OTG_HS;
  hpcd_USB_OTG_HS.Init.dev_endpoints = 9;
  hpcd_USB_OTG_HS.Init.speed = PCD_SPEED_HIGH;
  hpcd_USB_OTG_HS.Init.dma_enable = DISABLE;
  hpcd_USB_OTG_HS.Init.phy_itface = USB_OTG_ULPI_PHY;
  hpcd_USB_OTG_HS.Init.Sof_enable = DISABLE;
  hpcd_USB_OTG_HS.Init.low_power_enable = DISABLE;
  hpcd_USB_OTG_HS.Init.lpm_enable = DISABLE;
  hpcd_USB_OTG_HS.Init.vbus_sensing_enable = DISABLE;
  hpcd_USB_OTG_HS.Init.use_dedicated_ep1 = DISABLE;
  hpcd_USB_OTG_HS.Init.use_external_vbus = DISABLE;
  if (HAL_PCD_Init(&hpcd_USB_OTG_HS) != HAL_OK)
  {
    Error_Handler();
  }

}

static void MX_WWDG_Init(void)
{

  hwwdg.Instance = WWDG;
  hwwdg.Init.Prescaler = WWDG_PRESCALER_1;
  hwwdg.Init.Window = 64;
  hwwdg.Init.Counter = 128;
  hwwdg.Init.EWIMode = WWDG_EWI_DISABLE;
  if (HAL_WWDG_Init(&hwwdg) != HAL_OK)
  {
    Error_Handler();
  }

}

/* FMC initialization function */
static void MX_FMC_Init(void)
{

  FMC_SDRAM_TimingTypeDef SdramTiming = {0};

  /** Perform the SDRAM2 memory initialization sequence
  */
  hsdram2.Instance = FMC_SDRAM_DEVICE;
  /* hsdram2.Init */
  hsdram2.Init.SDBank = FMC_SDRAM_BANK1;
  hsdram2.Init.ColumnBitsNumber = FMC_SDRAM_COLUMN_BITS_NUM_8;
  hsdram2.Init.RowBitsNumber = FMC_SDRAM_ROW_BITS_NUM_12;
  hsdram2.Init.MemoryDataWidth = FMC_SDRAM_MEM_BUS_WIDTH_8;
  hsdram2.Init.InternalBankNumber = FMC_SDRAM_INTERN_BANKS_NUM_4;
  hsdram2.Init.CASLatency = FMC_SDRAM_CAS_LATENCY_1;
  hsdram2.Init.WriteProtection = FMC_SDRAM_WRITE_PROTECTION_DISABLE;
  hsdram2.Init.SDClockPeriod = FMC_SDRAM_CLOCK_DISABLE;
  hsdram2.Init.ReadBurst = FMC_SDRAM_RBURST_DISABLE;
  hsdram2.Init.ReadPipeDelay = FMC_SDRAM_RPIPE_DELAY_0;
  /* SdramTiming */
  SdramTiming.LoadToActiveDelay = 16;
  SdramTiming.ExitSelfRefreshDelay = 16;
  SdramTiming.SelfRefreshTime = 16;
  SdramTiming.RowCycleDelay = 16;
  SdramTiming.WriteRecoveryTime = 16;
  SdramTiming.RPDelay = 16;
  SdramTiming.RCDDelay = 16;

  if (HAL_SDRAM_Init(&hsdram2, &SdramTiming) != HAL_OK)
  {
    Error_Handler( );
  }

}

static void MX_GPIO_Init(void)
{
  GPIO_InitTypeDef GPIO_InitStruct = {0};

  /* GPIO Ports Clock Enable */
  __HAL_RCC_GPIOE_CLK_ENABLE();
  __HAL_RCC_GPIOG_CLK_ENABLE();
  __HAL_RCC_GPIOB_CLK_ENABLE();
  __HAL_RCC_GPIOD_CLK_ENABLE();
  __HAL_RCC_GPIOC_CLK_ENABLE();
  __HAL_RCC_GPIOA_CLK_ENABLE();
  __HAL_RCC_GPIOJ_CLK_ENABLE();
  __HAL_RCC_GPIOI_CLK_ENABLE();
  __HAL_RCC_GPIOK_CLK_ENABLE();
  __HAL_RCC_GPIOF_CLK_ENABLE();
  __HAL_RCC_GPIOH_CLK_ENABLE();

  /*Configure GPIO pin Output Level */
  HAL_GPIO_WritePin(DSI_RESET_GPIO_Port, DSI_RESET_Pin, GPIO_PIN_RESET);

  /*Configure GPIO pins : SAI1_FSA_Pin SAI1_SDB_Pin SAI1_SCKA_Pin SAI1_SDA_Pin */
  GPIO_InitStruct.Pin = SAI1_FSA_Pin|SAI1_SDB_Pin|SAI1_SCKA_Pin|SAI1_SDA_Pin;
  GPIO_InitStruct.Mode = GPIO_MODE_AF_PP;
  GPIO_InitStruct.Pull = GPIO_NOPULL;
  GPIO_InitStruct.Speed = GPIO_SPEED_FREQ_LOW;
  GPIO_InitStruct.Alternate = GPIO_AF6_SAI1;
  HAL_GPIO_Init(GPIOE, &GPIO_InitStruct);

  /*Configure GPIO pins : RMII_TXD1_Pin RMII_TXD0_Pin RMII_TX_EN_Pin */
  GPIO_InitStruct.Pin = RMII_TXD1_Pin|RMII_TXD0_Pin|RMII_TX_EN_Pin;
  GPIO_InitStruct.Mode = GPIO_MODE_AF_PP;
  GPIO_InitStruct.Pull = GPIO_NOPULL;
  GPIO_InitStruct.Speed = GPIO_SPEED_FREQ_VERY_HIGH;
  GPIO_InitStruct.Alternate = GPIO_AF11_ETH;
  HAL_GPIO_Init(GPIOG, &GPIO_InitStruct);

  /*Configure GPIO pins : ARDUINO_SCL_D15_Pin ARDUINO_SDA_D14_Pin */
  GPIO_InitStruct.Pin = ARDUINO_SCL_D15_Pin|ARDUINO_SDA_D14_Pin;
  GPIO_InitStruct.Mode = GPIO_MODE_AF_OD;
  GPIO_InitStruct.Pull = GPIO_PULLUP;
  GPIO_InitStruct.Speed = GPIO_SPEED_FREQ_LOW;
  GPIO_InitStruct.Alternate = GPIO_AF4_I2C1;
  HAL_GPIO_Init(GPIOB, &GPIO_InitStruct);

  /*Configure GPIO pins : uSD_D3_Pin uSD_D2_Pin */
  GPIO_InitStruct.Pin = uSD_D3_Pin|uSD_D2_Pin;
  GPIO_InitStruct.Mode = GPIO_MODE_AF_PP;
  GPIO_InitStruct.Pull = GPIO_NOPULL;
  GPIO_InitStruct.Speed = GPIO_SPEED_FREQ_VERY_HIGH;
  GPIO_InitStruct.Alternate = GPIO_AF10_SDMMC2;
  HAL_GPIO_Init(GPIOB, &GPIO_InitStruct);

  /*Configure GPIO pins : uSD_CMD_Pin uSD_CLK_Pin */
  GPIO_InitStruct.Pin = uSD_CMD_Pin|uSD_CLK_Pin;
  GPIO_InitStruct.Mode = GPIO_MODE_AF_PP;
  GPIO_InitStruct.Pull = GPIO_NOPULL;
  GPIO_InitStruct.Speed = GPIO_SPEED_FREQ_VERY_HIGH;
  GPIO_InitStruct.Alternate = GPIO_AF11_SDMMC2;
  HAL_GPIO_Init(GPIOD, &GPIO_InitStruct);

  /*Configure GPIO pin : WIFI_RX_Pin */
  GPIO_InitStruct.Pin = WIFI_RX_Pin;
  GPIO_InitStruct.Mode = GPIO_MODE_AF_PP;
  GPIO_InitStruct.Pull = GPIO_NOPULL;
  GPIO_InitStruct.Speed = GPIO_SPEED_FREQ_VERY_HIGH;
  GPIO_InitStruct.Alternate = GPIO_AF8_UART5;
  HAL_GPIO_Init(WIFI_RX_GPIO_Port, &GPIO_InitStruct);

  /*Configure GPIO pin : CEC_Pin */
  GPIO_InitStruct.Pin = CEC_Pin;
  GPIO_InitStruct.Mode = GPIO_MODE_AF_OD;
  GPIO_InitStruct.Pull = GPIO_NOPULL;
  GPIO_InitStruct.Speed = GPIO_SPEED_FREQ_LOW;
  GPIO_InitStruct.Alternate = GPIO_AF4_CEC;
  HAL_GPIO_Init(CEC_GPIO_Port, &GPIO_InitStruct);

  /*Configure GPIO pin : AUDIO_SDA_Pin */
  GPIO_InitStruct.Pin = AUDIO_SDA_Pin;
  GPIO_InitStruct.Mode = GPIO_MODE_AF_OD;
  GPIO_InitStruct.Pull = GPIO_PULLUP;
  GPIO_InitStruct.Speed = GPIO_SPEED_FREQ_VERY_HIGH;
  GPIO_InitStruct.Alternate = GPIO_AF11_I2C4;
  HAL_GPIO_Init(AUDIO_SDA_GPIO_Port, &GPIO_InitStruct);

  /*Configure GPIO pins : LD_USER1_Pin Audio_INT_Pin WIFI_RST_Pin ARD_D8_Pin
                           LD_USER2_Pin ARD_D7_Pin ARD_D4_Pin ARD_D2_Pin */
  GPIO_InitStruct.Pin = LD_USER1_Pin|Audio_INT_Pin|WIFI_RST_Pin|ARD_D8_Pin
                          |LD_USER2_Pin|ARD_D7_Pin|ARD_D4_Pin|ARD_D2_Pin;
  GPIO_InitStruct.Mode = GPIO_MODE_INPUT;
  GPIO_InitStruct.Pull = GPIO_NOPULL;
  HAL_GPIO_Init(GPIOJ, &GPIO_InitStruct);

  /*Configure GPIO pin : DFSDM_DATIN5_Pin */
  GPIO_InitStruct.Pin = DFSDM_DATIN5_Pin;
  GPIO_InitStruct.Mode = GPIO_MODE_AF_PP;
  GPIO_InitStruct.Pull = GPIO_NOPULL;
  GPIO_InitStruct.Speed = GPIO_SPEED_FREQ_LOW;
  GPIO_InitStruct.Alternate = GPIO_AF3_DFSDM1;
  HAL_GPIO_Init(DFSDM_DATIN5_GPIO_Port, &GPIO_InitStruct);

  /*Configure GPIO pin : ARD_D13_SCK_Pin */
  GPIO_InitStruct.Pin = ARD_D13_SCK_Pin;
  GPIO_InitStruct.Mode = GPIO_MODE_AF_PP;
  GPIO_InitStruct.Pull = GPIO_NOPULL;
  GPIO_InitStruct.Speed = GPIO_SPEED_FREQ_LOW;
  GPIO_InitStruct.Alternate = GPIO_AF5_SPI2;
  HAL_GPIO_Init(ARD_D13_SCK_GPIO_Port, &GPIO_InitStruct);

  /*Configure GPIO pins : NC4_Pin NC5_Pin uSD_Detect_Pin LCD_BL_CTRL_Pin */
  GPIO_InitStruct.Pin = NC4_Pin|NC5_Pin|uSD_Detect_Pin|LCD_BL_CTRL_Pin;
  GPIO_InitStruct.Mode = GPIO_MODE_INPUT;
  GPIO_InitStruct.Pull = GPIO_NOPULL;
  HAL_GPIO_Init(GPIOI, &GPIO_InitStruct);

  /*Configure GPIO pins : NC3_Pin NC2_Pin NC1_Pin NC8_Pin
                           NC7_Pin */
  GPIO_InitStruct.Pin = NC3_Pin|NC2_Pin|NC1_Pin|NC8_Pin
                          |NC7_Pin;
  GPIO_InitStruct.Mode = GPIO_MODE_INPUT;
  GPIO_InitStruct.Pull = GPIO_NOPULL;
  HAL_GPIO_Init(GPIOK, &GPIO_InitStruct);

  /*Configure GPIO pin : SPDIF_RX_Pin */
  GPIO_InitStruct.Pin = SPDIF_RX_Pin;
  GPIO_InitStruct.Mode = GPIO_MODE_AF_PP;
  GPIO_InitStruct.Pull = GPIO_NOPULL;
  GPIO_InitStruct.Speed = GPIO_SPEED_FREQ_LOW;
  GPIO_InitStruct.Alternate = GPIO_AF7_SPDIFRX;
  HAL_GPIO_Init(SPDIF_RX_GPIO_Port, &GPIO_InitStruct);

  /*Configure GPIO pins : uSD_D1_Pin uSD_D0_Pin */
  GPIO_InitStruct.Pin = uSD_D1_Pin|uSD_D0_Pin;
  GPIO_InitStruct.Mode = GPIO_MODE_AF_PP;
  GPIO_InitStruct.Pull = GPIO_NOPULL;
  GPIO_InitStruct.Speed = GPIO_SPEED_FREQ_VERY_HIGH;
  GPIO_InitStruct.Alternate = GPIO_AF11_SDMMC2;
  HAL_GPIO_Init(GPIOG, &GPIO_InitStruct);

  /*Configure GPIO pins : RMII_RXER_Pin OTG_FS_OverCurrent_Pin */
  GPIO_InitStruct.Pin = RMII_RXER_Pin|OTG_FS_OverCurrent_Pin;
  GPIO_InitStruct.Mode = GPIO_MODE_INPUT;
  GPIO_InitStruct.Pull = GPIO_NOPULL;
  HAL_GPIO_Init(GPIOD, &GPIO_InitStruct);

  /*Configure GPIO pin : DFSDM_CKOUT_Pin */
  GPIO_InitStruct.Pin = DFSDM_CKOUT_Pin;
  GPIO_InitStruct.Mode = GPIO_MODE_AF_PP;
  GPIO_InitStruct.Pull = GPIO_NOPULL;
  GPIO_InitStruct.Speed = GPIO_SPEED_FREQ_LOW;
  GPIO_InitStruct.Alternate = GPIO_AF3_DFSDM1;
  HAL_GPIO_Init(DFSDM_CKOUT_GPIO_Port, &GPIO_InitStruct);

  /*Configure GPIO pin : SPI2_NSS_Pin */
  GPIO_InitStruct.Pin = SPI2_NSS_Pin;
  GPIO_InitStruct.Mode = GPIO_MODE_AF_PP;
  GPIO_InitStruct.Pull = GPIO_NOPULL;
  GPIO_InitStruct.Speed = GPIO_SPEED_FREQ_VERY_HIGH;
  GPIO_InitStruct.Alternate = GPIO_AF5_SPI2;
  HAL_GPIO_Init(SPI2_NSS_GPIO_Port, &GPIO_InitStruct);

  /*Configure GPIO pin : DSI_RESET_Pin */
  GPIO_InitStruct.Pin = DSI_RESET_Pin;
  GPIO_InitStruct.Mode = GPIO_MODE_OUTPUT_PP;
  GPIO_InitStruct.Pull = GPIO_NOPULL;
  GPIO_InitStruct.Speed = GPIO_SPEED_FREQ_LOW;
  HAL_GPIO_Init(DSI_RESET_GPIO_Port, &GPIO_InitStruct);

  /*Configure GPIO pin : WIFI_TX_Pin */
  GPIO_InitStruct.Pin = WIFI_TX_Pin;
  GPIO_InitStruct.Mode = GPIO_MODE_AF_PP;
  GPIO_InitStruct.Pull = GPIO_NOPULL;
  GPIO_InitStruct.Speed = GPIO_SPEED_FREQ_VERY_HIGH;
  GPIO_InitStruct.Alternate = GPIO_AF8_UART5;
  HAL_GPIO_Init(WIFI_TX_GPIO_Port, &GPIO_InitStruct);

  /*Configure GPIO pin : VCP_RX_Pin */
  GPIO_InitStruct.Pin = VCP_RX_Pin;
  GPIO_InitStruct.Mode = GPIO_MODE_AF_PP;
  GPIO_InitStruct.Pull = GPIO_NOPULL;
  GPIO_InitStruct.Speed = GPIO_SPEED_FREQ_VERY_HIGH;
  GPIO_InitStruct.Alternate = GPIO_AF7_USART1;
  HAL_GPIO_Init(VCP_RX_GPIO_Port, &GPIO_InitStruct);

  /*Configure GPIO pin : VCP_TX_Pin */
  GPIO_InitStruct.Pin = VCP_TX_Pin;
  GPIO_InitStruct.Mode = GPIO_MODE_AF_PP;
  GPIO_InitStruct.Pull = GPIO_NOPULL;
  GPIO_InitStruct.Speed = GPIO_SPEED_FREQ_LOW;
  GPIO_InitStruct.Alternate = GPIO_AF7_USART1;
  HAL_GPIO_Init(VCP_TX_GPIO_Port, &GPIO_InitStruct);

  /*Configure GPIO pin : CEC_CLK_Pin */
  GPIO_InitStruct.Pin = CEC_CLK_Pin;
  GPIO_InitStruct.Mode = GPIO_MODE_AF_PP;
  GPIO_InitStruct.Pull = GPIO_NOPULL;
  GPIO_InitStruct.Speed = GPIO_SPEED_FREQ_LOW;
  GPIO_InitStruct.Alternate = GPIO_AF0_MCO;
  HAL_GPIO_Init(CEC_CLK_GPIO_Port, &GPIO_InitStruct);

  /*Configure GPIO pin : LCD_INT_Pin */
  GPIO_InitStruct.Pin = LCD_INT_Pin;
  GPIO_InitStruct.Mode = GPIO_MODE_EVT_RISING;
  GPIO_InitStruct.Pull = GPIO_NOPULL;
  HAL_GPIO_Init(LCD_INT_GPIO_Port, &GPIO_InitStruct);

  /*Configure GPIO pin : ARD_D5_PWM_Pin */
  GPIO_InitStruct.Pin = ARD_D5_PWM_Pin;
  GPIO_InitStruct.Mode = GPIO_MODE_AF_PP;
  GPIO_InitStruct.Pull = GPIO_NOPULL;
  GPIO_InitStruct.Speed = GPIO_SPEED_FREQ_LOW;
  GPIO_InitStruct.Alternate = GPIO_AF2_TIM3;
  HAL_GPIO_Init(ARD_D5_PWM_GPIO_Port, &GPIO_InitStruct);

  /*Configure GPIO pins : ARD_D0_RX_Pin ARDUINO_TX_D1_Pin */
  GPIO_InitStruct.Pin = ARD_D0_RX_Pin|ARDUINO_TX_D1_Pin;
  GPIO_InitStruct.Mode = GPIO_MODE_AF_PP;
  GPIO_InitStruct.Pull = GPIO_NOPULL;
  GPIO_InitStruct.Speed = GPIO_SPEED_FREQ_VERY_HIGH;
  GPIO_InitStruct.Alternate = GPIO_AF8_USART6;
  HAL_GPIO_Init(GPIOC, &GPIO_InitStruct);

  /*Configure GPIO pin : SAI1_MCLKA_Pin */
  GPIO_InitStruct.Pin = SAI1_MCLKA_Pin;
  GPIO_InitStruct.Mode = GPIO_MODE_AF_PP;
  GPIO_InitStruct.Pull = GPIO_NOPULL;
  GPIO_InitStruct.Speed = GPIO_SPEED_FREQ_LOW;
  GPIO_InitStruct.Alternate = GPIO_AF6_SAI1;
  HAL_GPIO_Init(SAI1_MCLKA_GPIO_Port, &GPIO_InitStruct);

  /*Configure GPIO pins : EXT_SDA_Pin EXT_SCL_Pin */
  GPIO_InitStruct.Pin = EXT_SDA_Pin|EXT_SCL_Pin;
  GPIO_InitStruct.Mode = GPIO_MODE_INPUT;
  GPIO_InitStruct.Pull = GPIO_NOPULL;
  HAL_GPIO_Init(GPIOG, &GPIO_InitStruct);

  /*Configure GPIO pin : ARD_D6_PWM_Pin */
  GPIO_InitStruct.Pin = ARD_D6_PWM_Pin;
  GPIO_InitStruct.Mode = GPIO_MODE_AF_PP;
  GPIO_InitStruct.Pull = GPIO_NOPULL;
  GPIO_InitStruct.Speed = GPIO_SPEED_FREQ_LOW;
  GPIO_InitStruct.Alternate = GPIO_AF3_TIM11;
  HAL_GPIO_Init(ARD_D6_PWM_GPIO_Port, &GPIO_InitStruct);

  /*Configure GPIO pin : ARD_D3_PWM_Pin */
  GPIO_InitStruct.Pin = ARD_D3_PWM_Pin;
  GPIO_InitStruct.Mode = GPIO_MODE_AF_PP;
  GPIO_InitStruct.Pull = GPIO_NOPULL;
  GPIO_InitStruct.Speed = GPIO_SPEED_FREQ_LOW;
  GPIO_InitStruct.Alternate = GPIO_AF3_TIM10;
  HAL_GPIO_Init(ARD_D3_PWM_GPIO_Port, &GPIO_InitStruct);

  /*Configure GPIO pins : ARDUINO_A1_Pin ARDUINO_A2_Pin ARDUINO_A3_Pin */
  GPIO_InitStruct.Pin = ARDUINO_A1_Pin|ARDUINO_A2_Pin|ARDUINO_A3_Pin;
  GPIO_InitStruct.Mode = GPIO_MODE_ANALOG;
  GPIO_InitStruct.Pull = GPIO_NOPULL;
  HAL_GPIO_Init(GPIOF, &GPIO_InitStruct);

  /*Configure GPIO pins : RMII_MDC_Pin RMII_RXD0_Pin RMII_RXD1_Pin */
  GPIO_InitStruct.Pin = RMII_MDC_Pin|RMII_RXD0_Pin|RMII_RXD1_Pin;
  GPIO_InitStruct.Mode = GPIO_MODE_AF_PP;
  GPIO_InitStruct.Pull = GPIO_NOPULL;
  GPIO_InitStruct.Speed = GPIO_SPEED_FREQ_VERY_HIGH;
  GPIO_InitStruct.Alternate = GPIO_AF11_ETH;
  HAL_GPIO_Init(GPIOC, &GPIO_InitStruct);

  /*Configure GPIO pin : ARD_A2_Pin */
  GPIO_InitStruct.Pin = ARD_A2_Pin;
  GPIO_InitStruct.Mode = GPIO_MODE_ANALOG;
  GPIO_InitStruct.Pull = GPIO_NOPULL;
  HAL_GPIO_Init(ARD_A2_GPIO_Port, &GPIO_InitStruct);

  /*Configure GPIO pin : AUDIO_SCL_Pin */
  GPIO_InitStruct.Pin = AUDIO_SCL_Pin;
  GPIO_InitStruct.Mode = GPIO_MODE_AF_OD;
  GPIO_InitStruct.Pull = GPIO_PULLUP;
  GPIO_InitStruct.Speed = GPIO_SPEED_FREQ_VERY_HIGH;
  GPIO_InitStruct.Alternate = GPIO_AF4_I2C4;
  HAL_GPIO_Init(AUDIO_SCL_GPIO_Port, &GPIO_InitStruct);

  /*Configure GPIO pins : RMII_REF_CLK_Pin RMII_MDIO_Pin RMII_CRS_DV_Pin */
  GPIO_InitStruct.Pin = RMII_REF_CLK_Pin|RMII_MDIO_Pin|RMII_CRS_DV_Pin;
  GPIO_InitStruct.Mode = GPIO_MODE_AF_PP;
  GPIO_InitStruct.Pull = GPIO_NOPULL;
  GPIO_InitStruct.Speed = GPIO_SPEED_FREQ_VERY_HIGH;
  GPIO_InitStruct.Alternate = GPIO_AF11_ETH;
  HAL_GPIO_Init(GPIOA, &GPIO_InitStruct);

  /*Configure GPIO pin : B_USER_Pin */
  GPIO_InitStruct.Pin = B_USER_Pin;
  GPIO_InitStruct.Mode = GPIO_MODE_IT_RISING;
  GPIO_InitStruct.Pull = GPIO_NOPULL;
  HAL_GPIO_Init(B_USER_GPIO_Port, &GPIO_InitStruct);

  /*Configure GPIO pins : ARD_A1_Pin ARD_A0_Pin */
  GPIO_InitStruct.Pin = ARD_A1_Pin|ARD_A0_Pin;
  GPIO_InitStruct.Mode = GPIO_MODE_ANALOG;
  GPIO_InitStruct.Pull = GPIO_NOPULL;
  HAL_GPIO_Init(GPIOA, &GPIO_InitStruct);

  /*Configure GPIO pin : SPDIF_TX_Pin */
  GPIO_InitStruct.Pin = SPDIF_TX_Pin;
  GPIO_InitStruct.Mode = GPIO_MODE_AF_PP;
  GPIO_InitStruct.Pull = GPIO_NOPULL;
  GPIO_InitStruct.Speed = GPIO_SPEED_FREQ_LOW;
  GPIO_InitStruct.Alternate = GPIO_AF10_SAI2;
  HAL_GPIO_Init(SPDIF_TX_GPIO_Port, &GPIO_InitStruct);

  /*Configure GPIO pin : PH7 */
  GPIO_InitStruct.Pin = GPIO_PIN_7;
  GPIO_InitStruct.Mode = GPIO_MODE_INPUT;
  GPIO_InitStruct.Pull = GPIO_NOPULL;
  HAL_GPIO_Init(GPIOH, &GPIO_InitStruct);

  /*Configure GPIO pin : ARDUINO_PWM_D6_Pin */
  GPIO_InitStruct.Pin = ARDUINO_PWM_D6_Pin;
  GPIO_InitStruct.Mode = GPIO_MODE_AF_PP;
  GPIO_InitStruct.Pull = GPIO_NOPULL;
  GPIO_InitStruct.Speed = GPIO_SPEED_FREQ_LOW;
  GPIO_InitStruct.Alternate = GPIO_AF9_TIM12;
  HAL_GPIO_Init(ARDUINO_PWM_D6_GPIO_Port, &GPIO_InitStruct);

  /*Configure GPIO pins : ARDUINO_MISO_D12_Pin ARDUINO_MOSI_PWM_D11_Pin */
  GPIO_InitStruct.Pin = ARDUINO_MISO_D12_Pin|ARDUINO_MOSI_PWM_D11_Pin;
  GPIO_InitStruct.Mode = GPIO_MODE_AF_PP;
  GPIO_InitStruct.Pull = GPIO_NOPULL;
  GPIO_InitStruct.Speed = GPIO_SPEED_FREQ_LOW;
  GPIO_InitStruct.Alternate = GPIO_AF5_SPI2;
  HAL_GPIO_Init(GPIOB, &GPIO_InitStruct);

}

/* USER CODE BEGIN 4 */
void LCDTask (void *argument) {
	BSP_LCD_LayerDefaultInit(0, LCD_FB_START_ADDRESS);
	BSP_LCD_SelectLayer(0);

	/* Touchscreen initialization */
	if (BSP_TS_Init(BSP_LCD_GetXSize(), BSP_LCD_GetYSize()) == TS_ERROR) {
	//printf("BSP_TS_Init error\n");
	}

	/* Clear the LCD */
	BSP_LCD_Clear(LCD_COLOR_WHITE);

	/* Set Touchscreen Demo1 description */
	BSP_LCD_SetTextColor(LCD_COLOR_BLUE);
	BSP_LCD_FillRect(0, 0, BSP_LCD_GetXSize(), 40);
	BSP_LCD_SetTextColor(LCD_COLOR_WHITE);
	BSP_LCD_SetBackColor(LCD_COLOR_BLUE);
	BSP_LCD_SetFont(&Font24);
	BSP_LCD_DisplayStringAt(0, 0, (uint8_t *)"Touchscreen basic test from RTOS task", CENTER_MODE);
}

/* USER CODE END 4 */

void StartDefaultTask(void *argument)
{
  for(;;)
  {
    osDelay(1);
  }
}

void HAL_TIM_PeriodElapsedCallback(TIM_HandleTypeDef *htim)
{
  if (htim->Instance == TIM6) {
    HAL_IncTick();
  }
}

void Error_Handler(void)
{
}

/************************ (C) COPYRIGHT STMicroelectronics *****END OF FILE****/
